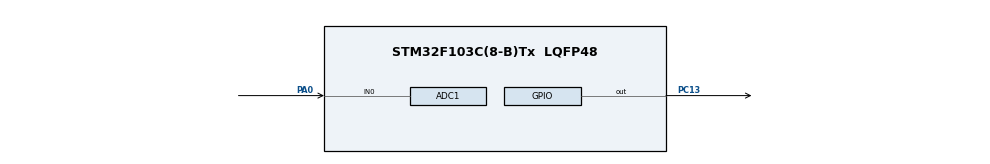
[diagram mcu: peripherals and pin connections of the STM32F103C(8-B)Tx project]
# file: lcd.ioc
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ADC1.Channel-1\#ChannelRegularConversion=ADC_CHANNEL_0
ADC1.NbrOfConversionFlag=1
ADC1.Rank-1\#ChannelRegularConversion=1
ADC1.SamplingTime-1\#ChannelRegularConversion=ADC_SAMPLETIME_1CYCLE_5
ADC1.master=1
Mcu.Family=STM32F1
Mcu.Name=STM32F103C(8-B)Tx
Mcu.Package=LQFP48
NVIC.ADC1_2_IRQn=true\:0\:0\:false\:false\:true\:true\:true\:true
NVIC.PriorityGroup=NVIC_PRIORITYGROUP_4
NVIC.TIM2_IRQn=true\:0\:0\:false\:false\:true\:true\:true\:true
PA0-WKUP.Signal=ADCx_IN0
PA13.Mode=Serial_Wire
PA13.Signal=SYS_JTMS-SWDIO
PA14.Mode=Serial_Wire
PA14.Signal=SYS_JTCK-SWCLK
PC13-TAMPER-RTC.Signal=GPIO_Output
PD0-OSC_IN.Mode=HSE-External-Oscillator
PD0-OSC_IN.Signal=RCC_OSC_IN
PD1-OSC_OUT.Mode=HSE-External-Oscillator
PD1-OSC_OUT.Signal=RCC_OSC_OUT
ProjectManager.HeapSize=0x200
ProjectManager.StackSize=0x400
ProjectManager.TargetToolchain=STM32CubeIDE
RCC.APB1Freq_Value=8000000
RCC.APB2Freq_Value=8000000
RCC.SYSCLKSource=RCC_SYSCLKSOURCE_HSE
SH.ADCx_IN0.0=ADC1_IN0,IN0
TIM2.AutoReloadPreload=TIM_AUTORELOAD_PRELOAD_ENABLE
TIM2.Period=4000
TIM2.Prescaler=1000
VP_TIM2_VS_ClockSourceINT.Mode=Internal
board=custom

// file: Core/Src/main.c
/* USER CODE BEGIN Header */
/**
  ******************************************************************************
  * @file           : main.c
  * @brief          : Main program body
  ******************************************************************************
  * @attention
  *
  * <h2><center>&copy; Copyright (c) 2023 STMicroelectronics.
  * All rights reserved.</center></h2>
  *
  * This software component is licensed by ST under BSD 3-Clause license,
  * the "License"; You may not use this file except in compliance with the
  * License. You may obtain a copy of the License at:
  *                        opensource.org/licenses/BSD-3-Clause
  *
  ******************************************************************************
  */
/* USER CODE END Header */
#include "main.h"
#include "LCD16x2.h"
#include "DWT_Delay.h"
#include <stdio.h>

ADC_HandleTypeDef hadc1;

TIM_HandleTypeDef htim2;

/* USER CODE BEGIN PV */
float ADCReading;
/* USER CODE END PV */

void SystemClock_Config(void);
static void MX_GPIO_Init(void);
static void MX_TIM2_Init(void);
static void MX_ADC1_Init(void);

int main(void)
{

  /* MCU Configuration--------------------------------------------------------*/

  /* Reset of all peripherals, Initializes the Flash interface and the Systick. */
  HAL_Init();

  /* Configure the system clock */
  SystemClock_Config();

  /* Initialize all configured peripherals */
  MX_GPIO_Init();
  MX_TIM2_Init();
  MX_ADC1_Init();
  /* USER CODE BEGIN 2 */
  HAL_TIM_Base_Start_IT(&htim2); //Start timer
  LCD_Init();

  LCD_Clear();
  LCD_SetCursor(1, 1);
  LCD_WriteString("CONVERSION ADC");
  DWT_Delay_ms(100);
  /* USER CODE END 2 */

  /* Infinite loop */
  while (1)
  {
	  int value = (ADCReading * 330 / 4096);
	  int value_dec = value % 100;
	  int value_int = (value - value_dec)/ 100;

	  char volts[10];

	  sprintf(volts, "%d,%02d V", value_int, value_dec);

	  LCD_SetCursor(2, 1);
	  LCD_WriteString(volts);
	  DWT_Delay_ms(500);
  }

}

void SystemClock_Config(void)
{
  RCC_OscInitTypeDef RCC_OscInitStruct = {0};
  RCC_ClkInitTypeDef RCC_ClkInitStruct = {0};
  RCC_PeriphCLKInitTypeDef PeriphClkInit = {0};

  /** Initializes the RCC Oscillators according to the specified parameters
  * in the RCC_OscInitTypeDef structure.
  */
  RCC_OscInitStruct.OscillatorType = RCC_OSCILLATORTYPE_HSE;
  RCC_OscInitStruct.HSEState = RCC_HSE_ON;
  RCC_OscInitStruct.PLL.PLLState = RCC_PLL_NONE;
  if (HAL_RCC_OscConfig(&RCC_OscInitStruct) != HAL_OK)
  {
    Error_Handler();
  }

  /** Initializes the CPU, AHB and APB buses clocks
  */
  RCC_ClkInitStruct.ClockType = RCC_CLOCKTYPE_HCLK|RCC_CLOCKTYPE_SYSCLK
                              |RCC_CLOCKTYPE_PCLK1|RCC_CLOCKTYPE_PCLK2;
  RCC_ClkInitStruct.SYSCLKSource = RCC_SYSCLKSOURCE_HSE;
  RCC_ClkInitStruct.AHBCLKDivider = RCC_SYSCLK_DIV1;
  RCC_ClkInitStruct.APB1CLKDivider = RCC_HCLK_DIV1;
  RCC_ClkInitStruct.APB2CLKDivider = RCC_HCLK_DIV1;

  if (HAL_RCC_ClockConfig(&RCC_ClkInitStruct, FLASH_LATENCY_0) != HAL_OK)
  {
    Error_Handler();
  }
  PeriphClkInit.PeriphClockSelection = RCC_PERIPHCLK_ADC;
  PeriphClkInit.AdcClockSelection = RCC_ADCPCLK2_DIV2;
  if (HAL_RCCEx_PeriphCLKConfig(&PeriphClkInit) != HAL_OK)
  {
    Error_Handler();
  }
}

static void MX_ADC1_Init(void)
{

  ADC_ChannelConfTypeDef sConfig = {0};

  /** Common config
  */
  hadc1.Instance = ADC1;
  hadc1.Init.ScanConvMode = ADC_SCAN_DISABLE;
  hadc1.Init.ContinuousConvMode = DISABLE;
  hadc1.Init.DiscontinuousConvMode = DISABLE;
  hadc1.Init.ExternalTrigConv = ADC_SOFTWARE_START;
  hadc1.Init.DataAlign = ADC_DATAALIGN_RIGHT;
  hadc1.Init.NbrOfConversion = 1;
  if (HAL_ADC_Init(&hadc1) != HAL_OK)
  {
    Error_Handler();
  }

  /** Configure Regular Channel
  */
  sConfig.Channel = ADC_CHANNEL_0;
  sConfig.Rank = ADC_REGULAR_RANK_1;
  sConfig.SamplingTime = ADC_SAMPLETIME_1CYCLE_5;
  if (HAL_ADC_ConfigChannel(&hadc1, &sConfig) != HAL_OK)
  {
    Error_Handler();
  }

}

static void MX_TIM2_Init(void)
{

  TIM_ClockConfigTypeDef sClockSourceConfig = {0};
  TIM_MasterConfigTypeDef sMasterConfig = {0};

  htim2.Instance = TIM2;
  htim2.Init.Prescaler = 1000;
  htim2.Init.CounterMode = TIM_COUNTERMODE_UP;
  htim2.Init.Period = 4000;
  htim2.Init.ClockDivision = TIM_CLOCKDIVISION_DIV1;
  htim2.Init.AutoReloadPreload = TIM_AUTORELOAD_PRELOAD_ENABLE;
  if (HAL_TIM_Base_Init(&htim2) != HAL_OK)
  {
    Error_Handler();
  }
  sClockSourceConfig.ClockSource = TIM_CLOCKSOURCE_INTERNAL;
  if (HAL_TIM_ConfigClockSource(&htim2, &sClockSourceConfig) != HAL_OK)
  {
    Error_Handler();
  }
  sMasterConfig.MasterOutputTrigger = TIM_TRGO_RESET;
  sMasterConfig.MasterSlaveMode = TIM_MASTERSLAVEMODE_DISABLE;
  if (HAL_TIMEx_MasterConfigSynchronization(&htim2, &sMasterConfig) != HAL_OK)
  {
    Error_Handler();
  }

}

static void MX_GPIO_Init(void)
{
  GPIO_InitTypeDef GPIO_InitStruct = {0};

  /* GPIO Ports Clock Enable */
  __HAL_RCC_GPIOC_CLK_ENABLE();
  __HAL_RCC_GPIOD_CLK_ENABLE();
  __HAL_RCC_GPIOA_CLK_ENABLE();

  /*Configure GPIO pin Output Level */
  HAL_GPIO_WritePin(GPIOC, GPIO_PIN_13, GPIO_PIN_RESET);

  /*Configure GPIO pin : PC13 */
  GPIO_InitStruct.Pin = GPIO_PIN_13;
  GPIO_InitStruct.Mode = GPIO_MODE_OUTPUT_PP;
  GPIO_InitStruct.Pull = GPIO_NOPULL;
  GPIO_InitStruct.Speed = GPIO_SPEED_FREQ_LOW;
  HAL_GPIO_Init(GPIOC, &GPIO_InitStruct);

}

void Error_Handler(void)
{
  __disable_irq();
  while (1)
  {
  }
}
